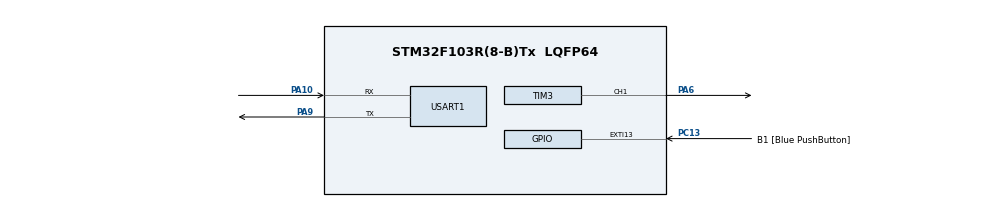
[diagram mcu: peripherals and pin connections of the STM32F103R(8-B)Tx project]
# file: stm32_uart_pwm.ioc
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Mcu.Family=STM32F1
Mcu.Name=STM32F103R(8-B)Tx
Mcu.Package=LQFP64
NVIC.EXTI15_10_IRQn=true\:0\:0\:false\:false\:true\:true\:true\:true
NVIC.PriorityGroup=NVIC_PRIORITYGROUP_4
NVIC.USART1_IRQn=true\:0\:0\:false\:false\:true\:true\:true\:true
PA10.Mode=Asynchronous
PA10.Signal=USART1_RX
PA13.GPIO_Label=TMS
PA13.Mode=Serial_Wire
PA13.Signal=SYS_JTMS-SWDIO
PA14.GPIO_Label=TCK
PA14.Mode=Serial_Wire
PA14.Signal=SYS_JTCK-SWCLK
PA6.Signal=S_TIM3_CH1
PA9.Mode=Asynchronous
PA9.Signal=USART1_TX
PB3.GPIO_Label=SWO
PB3.Signal=SYS_JTDO-TRACESWO
PC13-TAMPER-RTC.GPIO_Label=B1 [Blue PushButton]
PC13-TAMPER-RTC.GPIO_PuPd=GPIO_NOPULL
PC13-TAMPER-RTC.Signal=GPXTI13
PC14-OSC32_IN.Mode=LSE-External-Oscillator
PC14-OSC32_IN.Signal=RCC_OSC32_IN
PC15-OSC32_OUT.Mode=LSE-External-Oscillator
PC15-OSC32_OUT.Signal=RCC_OSC32_OUT
PD0-OSC_IN.Mode=HSE-External-Clock-Source
PD0-OSC_IN.Signal=RCC_OSC_IN
PD1-OSC_OUT.Mode=HSE-External-Clock-Source
PD1-OSC_OUT.Signal=RCC_OSC_OUT
ProjectManager.HeapSize=0x200
ProjectManager.StackSize=0x400
ProjectManager.TargetToolchain=STM32CubeIDE
RCC.AHBFreq_Value=72000000
RCC.APB1CLKDivider=RCC_HCLK_DIV2
RCC.APB1Freq_Value=36000000
RCC.APB1TimFreq_Value=72000000
RCC.APB2Freq_Value=72000000
RCC.APB2TimFreq_Value=72000000
RCC.HCLKFreq_Value=72000000
RCC.PLLMUL=RCC_PLL_MUL9
RCC.PLLSourceVirtual=RCC_PLLSOURCE_HSE
RCC.RTCClockSelection=RCC_RTCCLKSOURCE_LSE
RCC.SYSCLKFreq_VALUE=72000000
RCC.SYSCLKSource=RCC_SYSCLKSOURCE_PLLCLK
RCC.USBFreq_Value=72000000
SH.S_TIM3_CH1.0=TIM3_CH1,PWM Generation1 CH1
TIM3.AutoReloadPreload=TIM_AUTORELOAD_PRELOAD_DISABLE
TIM3.Channel-PWM\ Generation1\ CH1=TIM_CHANNEL_1
TIM3.Period=19999
TIM3.Prescaler=71
USART1.VirtualMode=VM_ASYNC
board=NUCLEO-F103RB

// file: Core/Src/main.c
/* USER CODE BEGIN Header */
/**
  ******************************************************************************
  * @file           : main.c
  * @brief          : Main program body
  ******************************************************************************
  * @attention
  *
  * Copyright (c) 2026 STMicroelectronics.
  * All rights reserved.
  *
  * This software is licensed under terms that can be found in the LICENSE file
  * in the root directory of this software component.
  * If no LICENSE file comes with this software, it is provided AS-IS.
  *
  ******************************************************************************
  */
/* USER CODE END Header */
#include "main.h"
#include "tim.h"
#include "usart.h"
#include "gpio.h"

void SystemClock_Config(void);

int main(void)
{

  /* MCU Configuration--------------------------------------------------------*/

  /* Reset of all peripherals, Initializes the Flash interface and the Systick. */
  LL_APB2_GRP1_EnableClock(LL_APB2_GRP1_PERIPH_AFIO);
  LL_APB1_GRP1_EnableClock(LL_APB1_GRP1_PERIPH_PWR);

  /* System interrupt init*/
  NVIC_SetPriorityGrouping(NVIC_PRIORITYGROUP_4);

  /** NOJTAG: JTAG-DP Disabled and SW-DP Enabled
  */
  LL_GPIO_AF_Remap_SWJ_NOJTAG();

  /* Configure the system clock */
  SystemClock_Config();

  /* Initialize all configured peripherals */
  MX_GPIO_Init();
  MX_TIM3_Init();
  MX_USART1_UART_Init();
  /* USER CODE BEGIN 2 */
  LL_TIM_OC_SetCompareCH1(TIM3, SERVO_PULSE_90DEG); /* start centered */
  LL_TIM_CC_EnableChannel(TIM3, LL_TIM_CHANNEL_CH1);
  LL_TIM_EnableCounter(TIM3);

  LL_USART_EnableIT_RXNE(USART1);
  /* USER CODE END 2 */

  /* Infinite loop */
  while (1)
  {

  }
}

void SystemClock_Config(void)
{
  LL_FLASH_SetLatency(LL_FLASH_LATENCY_2);
  while(LL_FLASH_GetLatency()!= LL_FLASH_LATENCY_2)
  {
  }
  LL_RCC_HSE_EnableBypass();
  LL_RCC_HSE_Enable();

   /* Wait till HSE is ready */
  while(LL_RCC_HSE_IsReady() != 1)
  {

  }
  LL_RCC_PLL_ConfigDomain_SYS(LL_RCC_PLLSOURCE_HSE_DIV_1, LL_RCC_PLL_MUL_9);
  LL_RCC_PLL_Enable();

   /* Wait till PLL is ready */
  while(LL_RCC_PLL_IsReady() != 1)
  {

  }
  LL_RCC_SetAHBPrescaler(LL_RCC_SYSCLK_DIV_1);
  LL_RCC_SetAPB1Prescaler(LL_RCC_APB1_DIV_2);
  LL_RCC_SetAPB2Prescaler(LL_RCC_APB2_DIV_1);
  LL_RCC_SetSysClkSource(LL_RCC_SYS_CLKSOURCE_PLL);

   /* Wait till System clock is ready */
  while(LL_RCC_GetSysClkSource() != LL_RCC_SYS_CLKSOURCE_STATUS_PLL)
  {

  }
  LL_Init1msTick(72000000);
  LL_SetSystemCoreClock(72000000);
}

void Error_Handler(void)
{
  __disable_irq();
  while (1)
  {
  }
}
